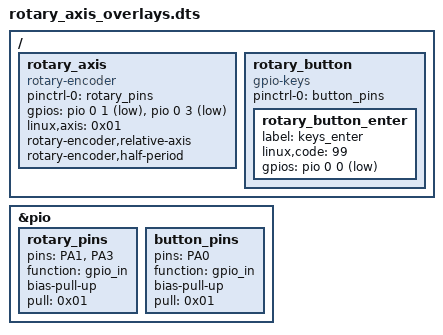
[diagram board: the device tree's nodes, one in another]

&pio {
	rotary_pins: rotary_pins {
		pins = "PA1","PA3";
		function = "gpio_in";
		bias-pull-up;
		pull = <0x01>;
	};

	button_pins: button_pins {
		pins = "PA0";
		function = "gpio_in";
		bias-pull-up;
		pull = <0x01>;
	};
};

/ {
	rotary_axis {
		compatible = "rotary-encoder";
		pinctrl-names = "default";
		pinctrl-0 = <&rotary_pins>;
		gpios = <&pio 0 1 1>, <&pio 0 3 1>;
		linux,axis = <0x01>;
		rotary-encoder,relative-axis;
		rotary-encoder,half-period;
		status = "okay";
	};

	rotary_button {
		compatible = "gpio-keys";
		pinctrl-names = "default";
		pinctrl-0 = <&button_pins>;
		status = "okay";

		rotary_button_enter {
			label = "keys_enter";
			linux,code = <99>;
			gpios = <&pio 0 0 1>;
		};
	};
};

